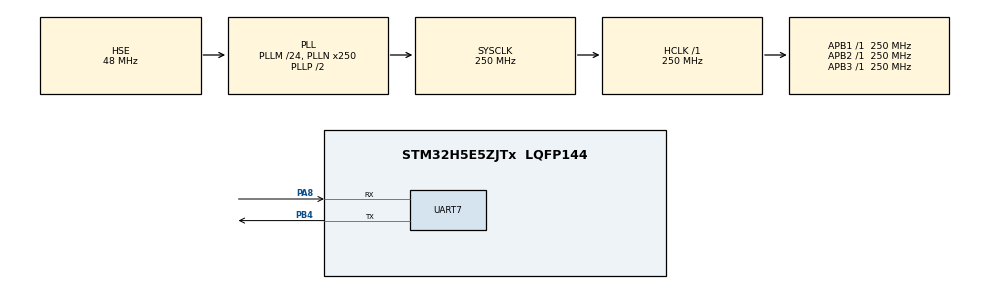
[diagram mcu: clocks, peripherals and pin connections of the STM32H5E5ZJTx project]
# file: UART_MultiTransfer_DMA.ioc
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BOOTPATH.BootPathName=LEGACY
BOOTPATH.UserSelectedBootPath=LEGACY
CORTEX_M33_NS.userName=CORTEX_M33
GPDMA1.TRANSFEREVENTMODE_LL_GPDMACH0=DMA_TCEM_LAST_LL_ITEM_TRANSFER
GPDMA1.TRANSFEREVENTMODE_LL_GPDMACH1=DMA_TCEM_LAST_LL_ITEM_TRANSFER
Linkedlist.MDMA_Channel0.GP_SW.0.BlkHWRequest=DMA_BREQ_SINGLE_BURST
Linkedlist.MDMA_Channel0.GP_SW.0.DataHandling=NONE
Linkedlist.MDMA_Channel0.GP_SW.0.DataSize=0
Linkedlist.MDMA_Channel0.GP_SW.0.DestBurstLength=1
Linkedlist.MDMA_Channel0.GP_SW.0.DestDataWidth=DMA_DEST_DATAWIDTH_BYTE
Linkedlist.MDMA_Channel0.GP_SW.0.DestInc=DMA_DINC_FIXED
Linkedlist.MDMA_Channel0.GP_SW.0.Direction=DMA_MEMORY_TO_PERIPH
Linkedlist.MDMA_Channel0.GP_SW.0.DstAddress=0
Linkedlist.MDMA_Channel0.GP_SW.0.Instance=MDMA_Channel0
Linkedlist.MDMA_Channel0.GP_SW.0.LL_MASTERDMA=GPDMA1
Linkedlist.MDMA_Channel0.GP_SW.0.LL_NAME=UART_Tx_Queue
Linkedlist.MDMA_Channel0.GP_SW.0.LL_TYPE=LINEAR
Linkedlist.MDMA_Channel0.GP_SW.0.Mode=DMA_NORMAL
Linkedlist.MDMA_Channel0.GP_SW.0.NODE_NAME=Node1_tx
Linkedlist.MDMA_Channel0.GP_SW.0.Requestforcodegen=GPDMA1_REQUEST_UART7_TX
Linkedlist.MDMA_Channel0.GP_SW.0.SrcAddress=0
Linkedlist.MDMA_Channel0.GP_SW.0.SrcBurstLength=1
Linkedlist.MDMA_Channel0.GP_SW.0.SrcDataWidth=DMA_SRC_DATAWIDTH_BYTE
Linkedlist.MDMA_Channel0.GP_SW.0.SrcInc=DMA_SINC_INCREMENTED
Linkedlist.MDMA_Channel0.GP_SW.0.TransferAllocatedPortSrc=DMA_SRC_ALLOCATED_PORT0
Linkedlist.MDMA_Channel0.GP_SW.0.TransferEventMode=DMA_TCEM_LAST_LL_ITEM_TRANSFER
Linkedlist.MDMA_Channel0.GP_SW.0.TriggerPolarity=DMA_TRIG_POLARITY_MASKED
Linkedlist.MDMA_Channel0.GP_SW.1.BlkHWRequest=DMA_BREQ_SINGLE_BURST
Linkedlist.MDMA_Channel0.GP_SW.1.DataHandling=NONE
Linkedlist.MDMA_Channel0.GP_SW.1.DataSize=138
Linkedlist.MDMA_Channel0.GP_SW.1.DestBurstLength=1
Linkedlist.MDMA_Channel0.GP_SW.1.DestDataWidth=DMA_DEST_DATAWIDTH_BYTE
Linkedlist.MDMA_Channel0.GP_SW.1.DestInc=DMA_DINC_FIXED
Linkedlist.MDMA_Channel0.GP_SW.1.Direction=DMA_MEMORY_TO_PERIPH
Linkedlist.MDMA_Channel0.GP_SW.1.DstAddress=(uint32_t)&huart7.Instance->TDR
Linkedlist.MDMA_Channel0.GP_SW.1.Instance=MDMA_Channel0
Linkedlist.MDMA_Channel0.GP_SW.1.LL_MASTERDMA=GPDMA1
Linkedlist.MDMA_Channel0.GP_SW.1.LL_NAME=UART_Tx_Queue
Linkedlist.MDMA_Channel0.GP_SW.1.LL_TYPE=LINEAR
Linkedlist.MDMA_Channel0.GP_SW.1.Mode=DMA_NORMAL
Linkedlist.MDMA_Channel0.GP_SW.1.NODE_NAME=Node2_tx
Linkedlist.MDMA_Channel0.GP_SW.1.Requestforcodegen=GPDMA1_REQUEST_UART7_TX
Linkedlist.MDMA_Channel0.GP_SW.1.SrcAddress=(uint32_t)aTxBuffer1
Linkedlist.MDMA_Channel0.GP_SW.1.SrcBurstLength=1
Linkedlist.MDMA_Channel0.GP_SW.1.SrcDataWidth=DMA_SRC_DATAWIDTH_BYTE
Linkedlist.MDMA_Channel0.GP_SW.1.SrcInc=DMA_SINC_INCREMENTED
Linkedlist.MDMA_Channel0.GP_SW.1.TransferAllocatedPortSrc=DMA_SRC_ALLOCATED_PORT0
Linkedlist.MDMA_Channel0.GP_SW.1.TransferEventMode=DMA_TCEM_LAST_LL_ITEM_TRANSFER
Linkedlist.MDMA_Channel0.GP_SW.1.TriggerPolarity=DMA_TRIG_POLARITY_MASKED
Linkedlist.MDMA_Channel0.GP_SW.2.BlkHWRequest=DMA_BREQ_SINGLE_BURST
Linkedlist.MDMA_Channel0.GP_SW.2.DataHandling=NONE
Linkedlist.MDMA_Channel0.GP_SW.2.DataSize=138
Linkedlist.MDMA_Channel0.GP_SW.2.DestBurstLength=1
Linkedlist.MDMA_Channel0.GP_SW.2.DestDataWidth=DMA_DEST_DATAWIDTH_BYTE
Linkedlist.MDMA_Channel0.GP_SW.2.DestInc=DMA_DINC_FIXED
Linkedlist.MDMA_Channel0.GP_SW.2.Direction=DMA_MEMORY_TO_PERIPH
Linkedlist.MDMA_Channel0.GP_SW.2.DstAddress=(uint32_t)&huart7.Instance->TDR
Linkedlist.MDMA_Channel0.GP_SW.2.Instance=MDMA_Channel0
Linkedlist.MDMA_Channel0.GP_SW.2.LL_MASTERDMA=GPDMA1
Linkedlist.MDMA_Channel0.GP_SW.2.LL_NAME=UART_Tx_Queue
Linkedlist.MDMA_Channel0.GP_SW.2.LL_TYPE=LINEAR
Linkedlist.MDMA_Channel0.GP_SW.2.Mode=DMA_NORMAL
Linkedlist.MDMA_Channel0.GP_SW.2.NODE_NAME=Node3_tx
Linkedlist.MDMA_Channel0.GP_SW.2.Requestforcodegen=GPDMA1_REQUEST_UART7_TX
Linkedlist.MDMA_Channel0.GP_SW.2.SrcAddress=(uint32_t)aTxBuffer2
Linkedlist.MDMA_Channel0.GP_SW.2.SrcBurstLength=1
Linkedlist.MDMA_Channel0.GP_SW.2.SrcDataWidth=DMA_SRC_DATAWIDTH_BYTE
Linkedlist.MDMA_Channel0.GP_SW.2.SrcInc=DMA_SINC_INCREMENTED
Linkedlist.MDMA_Channel0.GP_SW.2.TransferAllocatedPortSrc=DMA_SRC_ALLOCATED_PORT0
Linkedlist.MDMA_Channel0.GP_SW.2.TransferEventMode=DMA_TCEM_LAST_LL_ITEM_TRANSFER
Linkedlist.MDMA_Channel0.GP_SW.2.TriggerPolarity=DMA_TRIG_POLARITY_MASKED
Linkedlist.MDMA_Channel0.Request0=GP_SW
Linkedlist.MDMA_Channel0.Request1=GP_SW
Linkedlist.MDMA_Channel0.Request2=GP_SW
Linkedlist.MDMA_Channel0.RequestsNb=3
Linkedlist.MDMA_Channel1.GP_SW.0.BlkHWRequest=DMA_BREQ_SINGLE_BURST
Linkedlist.MDMA_Channel1.GP_SW.0.DataHandling=NONE
Linkedlist.MDMA_Channel1.GP_SW.0.DataSize=0
Linkedlist.MDMA_Channel1.GP_SW.0.DestBurstLength=1
Linkedlist.MDMA_Channel1.GP_SW.0.DestDataWidth=DMA_DEST_DATAWIDTH_BYTE
Linkedlist.MDMA_Channel1.GP_SW.0.DestInc=DMA_DINC_INCREMENTED
Linkedlist.MDMA_Channel1.GP_SW.0.Direction=DMA_PERIPH_TO_MEMORY
Linkedlist.MDMA_Channel1.GP_SW.0.DstAddress=0
Linkedlist.MDMA_Channel1.GP_SW.0.Instance=MDMA_Channel1
Linkedlist.MDMA_Channel1.GP_SW.0.LL_MASTERDMA=GPDMA1
Linkedlist.MDMA_Channel1.GP_SW.0.LL_NAME=UART_Rx_Queue
Linkedlist.MDMA_Channel1.GP_SW.0.LL_TYPE=LINEAR
Linkedlist.MDMA_Channel1.GP_SW.0.Mode=DMA_NORMAL
Linkedlist.MDMA_Channel1.GP_SW.0.NODE_NAME=Node1_rx
Linkedlist.MDMA_Channel1.GP_SW.0.Requestforcodegen=GPDMA1_REQUEST_UART7_RX
Linkedlist.MDMA_Channel1.GP_SW.0.SrcAddress=0
Linkedlist.MDMA_Channel1.GP_SW.0.SrcBurstLength=1
Linkedlist.MDMA_Channel1.GP_SW.0.SrcDataWidth=DMA_SRC_DATAWIDTH_BYTE
Linkedlist.MDMA_Channel1.GP_SW.0.SrcInc=DMA_SINC_FIXED
Linkedlist.MDMA_Channel1.GP_SW.0.TransferAllocatedPortSrc=DMA_SRC_ALLOCATED_PORT0
Linkedlist.MDMA_Channel1.GP_SW.0.TransferEventMode=DMA_TCEM_LAST_LL_ITEM_TRANSFER
Linkedlist.MDMA_Channel1.GP_SW.0.TriggerPolarity=DMA_TRIG_POLARITY_MASKED
Linkedlist.MDMA_Channel1.GP_SW.1.BlkHWRequest=DMA_BREQ_SINGLE_BURST
Linkedlist.MDMA_Channel1.GP_SW.1.DataHandling=NONE
Linkedlist.MDMA_Channel1.GP_SW.1.DataSize=138
Linkedlist.MDMA_Channel1.GP_SW.1.DestBurstLength=1
Linkedlist.MDMA_Channel1.GP_SW.1.DestDataWidth=DMA_DEST_DATAWIDTH_BYTE
Linkedlist.MDMA_Channel1.GP_SW.1.DestInc=DMA_DINC_INCREMENTED
Linkedlist.MDMA_Channel1.GP_SW.1.Direction=DMA_PERIPH_TO_MEMORY
Linkedlist.MDMA_Channel1.GP_SW.1.DstAddress=(uint32_t)aRxBuffer1
Linkedlist.MDMA_Channel1.GP_SW.1.Instance=MDMA_Channel1
Linkedlist.MDMA_Channel1.GP_SW.1.LL_MASTERDMA=GPDMA1
Linkedlist.MDMA_Channel1.GP_SW.1.LL_NAME=UART_Rx_Queue
Linkedlist.MDMA_Channel1.GP_SW.1.LL_TYPE=LINEAR
Linkedlist.MDMA_Channel1.GP_SW.1.Mode=DMA_NORMAL
Linkedlist.MDMA_Channel1.GP_SW.1.NODE_NAME=Node2_rx
Linkedlist.MDMA_Channel1.GP_SW.1.Requestforcodegen=GPDMA1_REQUEST_UART7_RX
Linkedlist.MDMA_Channel1.GP_SW.1.SrcAddress=(uint32_t)&huart7.Instance->RDR
Linkedlist.MDMA_Channel1.GP_SW.1.SrcBurstLength=1
Linkedlist.MDMA_Channel1.GP_SW.1.SrcDataWidth=DMA_SRC_DATAWIDTH_BYTE
Linkedlist.MDMA_Channel1.GP_SW.1.SrcInc=DMA_SINC_FIXED
Linkedlist.MDMA_Channel1.GP_SW.1.TransferAllocatedPortSrc=DMA_SRC_ALLOCATED_PORT0
Linkedlist.MDMA_Channel1.GP_SW.1.TransferEventMode=DMA_TCEM_LAST_LL_ITEM_TRANSFER
Linkedlist.MDMA_Channel1.GP_SW.1.TriggerPolarity=DMA_TRIG_POLARITY_MASKED
Linkedlist.MDMA_Channel1.GP_SW.2.BlkHWRequest=DMA_BREQ_SINGLE_BURST
Linkedlist.MDMA_Channel1.GP_SW.2.DataHandling=NONE
Linkedlist.MDMA_Channel1.GP_SW.2.DataSize=138
Linkedlist.MDMA_Channel1.GP_SW.2.DestBurstLength=1
Linkedlist.MDMA_Channel1.GP_SW.2.DestDataWidth=DMA_DEST_DATAWIDTH_BYTE
Linkedlist.MDMA_Channel1.GP_SW.2.DestInc=DMA_DINC_INCREMENTED
Linkedlist.MDMA_Channel1.GP_SW.2.Direction=DMA_PERIPH_TO_MEMORY
Linkedlist.MDMA_Channel1.GP_SW.2.DstAddress=(uint32_t)aRxBuffer2
Linkedlist.MDMA_Channel1.GP_SW.2.Instance=MDMA_Channel1
Linkedlist.MDMA_Channel1.GP_SW.2.LL_MASTERDMA=GPDMA1
Linkedlist.MDMA_Channel1.GP_SW.2.LL_NAME=UART_Rx_Queue
Linkedlist.MDMA_Channel1.GP_SW.2.LL_TYPE=LINEAR
Linkedlist.MDMA_Channel1.GP_SW.2.Mode=DMA_NORMAL
Linkedlist.MDMA_Channel1.GP_SW.2.NODE_NAME=Node3_rx
Linkedlist.MDMA_Channel1.GP_SW.2.Requestforcodegen=GPDMA1_REQUEST_UART7_RX
Linkedlist.MDMA_Channel1.GP_SW.2.SrcAddress=(uint32_t)&huart7.Instance->RDR
Linkedlist.MDMA_Channel1.GP_SW.2.SrcBurstLength=1
Linkedlist.MDMA_Channel1.GP_SW.2.SrcDataWidth=DMA_SRC_DATAWIDTH_BYTE
Linkedlist.MDMA_Channel1.GP_SW.2.SrcInc=DMA_SINC_FIXED
Linkedlist.MDMA_Channel1.GP_SW.2.TransferAllocatedPortSrc=DMA_SRC_ALLOCATED_PORT0
Linkedlist.MDMA_Channel1.GP_SW.2.TransferEventMode=DMA_TCEM_LAST_LL_ITEM_TRANSFER
Linkedlist.MDMA_Channel1.GP_SW.2.TriggerPolarity=DMA_TRIG_POLARITY_MASKED
Linkedlist.MDMA_Channel1.Request0=GP_SW
Linkedlist.MDMA_Channel1.Request1=GP_SW
Linkedlist.MDMA_Channel1.Request2=GP_SW
Linkedlist.MDMA_Channel1.RequestsNb=3
Linkedlist.RequestSet0=MDMA_Channel0
Linkedlist.RequestSet1=MDMA_Channel1
Linkedlist.RequestSetsNb=2
Mcu.Family=STM32H5
Mcu.Name=STM32H5E5ZJTx
Mcu.Package=LQFP144
NVIC.GPDMA1_Channel0_IRQn=true\:0\:0\:false\:false\:true\:true\:true\:true
NVIC.GPDMA1_Channel1_IRQn=true\:0\:0\:false\:false\:true\:true\:true\:true
NVIC.PriorityGroup=NVIC_PRIORITYGROUP_4
NVIC.UART7_IRQn=true\:0\:0\:false\:false\:true\:true\:true\:true
PA8.GPIO_PuPd=GPIO_PULLUP
PA8.GPIO_Speed=GPIO_SPEED_FREQ_VERY_HIGH
PA8.Mode=Asynchronous
PA8.Signal=UART7_RX
PB4\ (NJTRST).GPIO_PuPd=GPIO_PULLUP
PB4\ (NJTRST).GPIO_Speed=GPIO_SPEED_FREQ_VERY_HIGH
PB4\ (NJTRST).Mode=Asynchronous
PB4\ (NJTRST).Signal=UART7_TX
PH0-OSC_IN(PH0).Mode=HSE-External-Oscillator
PH0-OSC_IN(PH0).Signal=RCC_OSC_IN
PH1-OSC_OUT(PH1).Mode=HSE-External-Oscillator
PH1-OSC_OUT(PH1).Signal=RCC_OSC_OUT
ProjectManager.HeapSize=0x200
ProjectManager.StackSize=0x400
ProjectManager.TargetToolchain=EWARM V9.20
RCC.ADCFreq_Value=250000000
RCC.AHBFreq_Value=250000000
RCC.APB1Freq_Value=250000000
RCC.APB1TimFreq_Value=250000000
RCC.APB2Freq_Value=250000000
RCC.APB2TimFreq_Value=250000000
RCC.APB3Freq_Value=250000000
RCC.CSI_VALUE=4000000
RCC.CortexFreq_Value=250000000
RCC.EPOD_VALUE=48000000
RCC.HCLKFreq_Value=250000000
RCC.HSE_VALUE=48000000
RCC.HSI48_VALUE=48000000
RCC.HSI_VALUE=64000000
RCC.LSE_VALUE=32768
RCC.LSIRC_VALUE=32000
RCC.PLLM=24
RCC.PLLN=250
RCC.PLLSourceVirtual=RCC_PLL1_SOURCE_HSE
RCC.SYSCLKFreq_VALUE=250000000
RCC.SYSCLKSource=RCC_SYSCLKSOURCE_PLLCLK
RCC.USBFreq_Value=258000000
RCC.VCOOutputFreq_Value=500000000
VP_BOOTPATH_VS_BOOTPATH.Mode=BP_Activate
VP_CORTEX_M33_NS_VS_Hclk.Mode=Hclk_Mode
VP_GPDMA1_VS_GPDMACH0.Mode=LINKEDLIST_GPDMACH0
VP_GPDMA1_VS_GPDMACH1.Mode=LINKEDLIST_GPDMACH1
VP_ICACHE_VS_ICACHE.Mode=DefaultMode
VP_PWR_VS_LPOM.Mode=PowerOptimisation
VP_PWR_VS_SECSignals.Mode=Security/Privilege
board=custom

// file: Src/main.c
/* USER CODE BEGIN Header */
/**
  ******************************************************************************
  * @file           : main.c
  * @brief          : Main program body
  ******************************************************************************
  * @attention
  *
  * Copyright (c) 2025 STMicroelectronics.
  * All rights reserved.
  *
  * This software is licensed under terms that can be found in the LICENSE file
  * in the root directory of this software component.
  * If no LICENSE file comes with this software, it is provided AS-IS.
  *
  ******************************************************************************
  */
/* USER CODE END Header */
#include "main.h"

/* USER CODE BEGIN Includes */
#include "linked_list.h"
/* USER CODE END Includes */

/* USER CODE BEGIN PD */
//#define TRANSMITTER_BOARD
/* USER CODE END PD */

DMA_HandleTypeDef handle_GPDMA1_Channel1;
DMA_HandleTypeDef handle_GPDMA1_Channel0;

UART_HandleTypeDef huart7;

/* USER CODE BEGIN PV */
__IO ITStatus UartReady = RESET;
__IO uint32_t UserButtonStatus = 0;  /* set to 1 after User Button interrupt  */
extern DMA_QListTypeDef UART_Tx_Queue;
extern DMA_QListTypeDef UART_Rx_Queue;

/* Buffers used for transmission :
   Size should be a Multiple of cache line size (32 bytes) */
ALIGN_32BYTES (uint8_t aTxBuffer0[]) = "0*****UART_MultiTransfer communication based on DMA Linkedlist*****  *****UART_MultiTransfer communication based on DMA Linkedlist*****0\r\n";
ALIGN_32BYTES (uint8_t aTxBuffer1[]) = "1*****UART_MultiTransfer communication based on DMA Linkedlist*****  *****UART_MultiTransfer communication based on DMA Linkedlist*****1\r\n";
ALIGN_32BYTES (uint8_t aTxBuffer2[]) = "2*****UART_MultiTransfer communication based on DMA Linkedlist*****  *****UART_MultiTransfer communication based on DMA Linkedlist*****2\r\n";
/* Buffer used for reception :
   Size should be a Multiple of cache line size (32 bytes) */
ALIGN_32BYTES (uint8_t aRxBuffer0[RXBUFFERSIZE]);
ALIGN_32BYTES (uint8_t aRxBuffer1[RXBUFFERSIZE]);
ALIGN_32BYTES (uint8_t aRxBuffer2[RXBUFFERSIZE]);
/* USER CODE END PV */

void SystemClock_Config(void);
static void MX_GPIO_Init(void);
static void MX_GPDMA1_Init(void);
static void MX_ICACHE_Init(void);
static void MX_UART7_Init(void);
/* USER CODE BEGIN PFP */
static uint16_t Buffercmp(uint8_t* pBuffer1, uint8_t* pBuffer2, uint16_t BufferLength);
/* USER CODE END PFP */

int main(void)
{

  /* MCU Configuration--------------------------------------------------------*/

  /* Reset of all peripherals, Initializes the Flash interface and the Systick. */
  HAL_Init();

  /* Configure the system clock */
  SystemClock_Config();

  /* USER CODE BEGIN SysInit */
  /* Configure LED1 */
  BSP_LED_Init(LED_GREEN);
  BSP_LED_Init(LED_RED);
  BSP_LED_Init(LED_BLUE);
  /* USER CODE END SysInit */

  /* Initialize all configured peripherals */
  MX_GPIO_Init();
  MX_GPDMA1_Init();
  MX_ICACHE_Init();
  MX_UART7_Init();
  /* USER CODE BEGIN 2 */
  MX_UART_Tx_Queue_Config();
  MX_UART_Rx_Queue_Config();
  /* Link UART queue to DMA channel */
  HAL_DMAEx_List_LinkQ(&handle_GPDMA1_Channel0, &UART_Tx_Queue);

  /* Associate the initialized GPDMA handle to the UART handle */
  __HAL_LINKDMA(&huart7, hdmatx, handle_GPDMA1_Channel0);
  /* Link UART queue to DMA channel */
  HAL_DMAEx_List_LinkQ(&handle_GPDMA1_Channel1, &UART_Rx_Queue);

  /* Associate the initialized GPDMA handle to the UART handle */
  __HAL_LINKDMA(&huart7, hdmarx, handle_GPDMA1_Channel1);

#ifdef TRANSMITTER_BOARD

  /* Configure User push-button in Interrupt mode */
  BSP_PB_Init(BUTTON_USER, BUTTON_MODE_EXTI);

  /* Wait for User push-button press before starting the Communication.
     In the meantime, LED2 is blinking */
  while(UserButtonStatus == 0)
  {
      /* Toggle LED3*/
      BSP_LED_Toggle(LED_BLUE);
      HAL_Delay(100);
  }

  BSP_LED_Off(LED_BLUE);

  /* The board sends the message and expects to receive it back */

  /*##-2- Start the transmission process #####################################*/
  /* While the UART in reception process, user can transmit data through
     "aTxBuffer" buffer */
  if(HAL_UART_Transmit_DMA(&huart7, (uint8_t*)aTxBuffer0, TXBUFFERSIZE)!= HAL_OK)
  {
    Error_Handler();
  }

  /*##-3- Wait for the end of the transfer ###################################*/
  while (UartReady != SET)
  {
  }

  /* Reset transmission flag */
  UartReady = RESET;

  /*##-4- Put UART peripheral in reception process ###########################*/
  if(HAL_UART_Receive_DMA(&huart7, (uint8_t *)aRxBuffer0, RXBUFFERSIZE) != HAL_OK)
  {
    Error_Handler();
  }

#else

  /* The board receives the message and sends it back */

  /*##-2- Put UART peripheral in reception process ###########################*/
  if(HAL_UART_Receive_DMA(&huart7, (uint8_t *)aRxBuffer0, RXBUFFERSIZE) != HAL_OK)
  {
    Error_Handler();
  }

  /*##-3- Wait for the end of the transfer ###################################*/
  /* While waiting for message to come from the other board, LED2 is
     blinking according to the following pattern: a double flash every half-second */
  while (UartReady != SET)
  {
      BSP_LED_On(LED_BLUE);
      HAL_Delay(100);
      BSP_LED_Off(LED_BLUE);
      HAL_Delay(100);
      BSP_LED_On(LED_BLUE);
      HAL_Delay(100);
      BSP_LED_Off(LED_BLUE);
      HAL_Delay(500);
  }

  /* Reset transmission flag */
  UartReady = RESET;
  BSP_LED_Off(LED_BLUE);

  /*##-4- Start the transmission process #####################################*/
  if(HAL_UART_Transmit_DMA(&huart7, (uint8_t*)aTxBuffer0, TXBUFFERSIZE)!= HAL_OK)
  {
    Error_Handler();
  }

#endif /* TRANSMITTER_BOARD */

  /*##-5- Wait for the end of the transfer ###################################*/
  while (UartReady != SET)
  {
  }

  /* Reset transmission flag */
  UartReady = RESET;

  /*##-6- Compare the sent and received buffers ##############################*/
  if((Buffercmp((uint8_t*)aTxBuffer0,(uint8_t*)aRxBuffer0,RXBUFFERSIZE) != 0) ||\
     (Buffercmp((uint8_t*)aTxBuffer1,(uint8_t*)aRxBuffer1,RXBUFFERSIZE) != 0) ||\
     (Buffercmp((uint8_t*)aTxBuffer2,(uint8_t*)aRxBuffer2,RXBUFFERSIZE) != 0))
  {
    Error_Handler();
  }

  /* Turn on LED1 if test passes then enter infinite loop */
  BSP_LED_On(LED_GREEN);
  /* USER CODE END 2 */

  /* Infinite loop */
  while (1)
  {

  }
}

void SystemClock_Config(void)
{
  RCC_OscInitTypeDef RCC_OscInitStruct = {0};
  RCC_ClkInitTypeDef RCC_ClkInitStruct = {0};

  /** Configure the main internal regulator output voltage
  */
  __HAL_PWR_VOLTAGESCALING_CONFIG(PWR_REGULATOR_VOLTAGE_SCALE0);

  while(!__HAL_PWR_GET_FLAG(PWR_FLAG_VOSRDY)) {}

  /** Initializes the RCC Oscillators according to the specified parameters
  * in the RCC_OscInitTypeDef structure.
  */
  RCC_OscInitStruct.OscillatorType = RCC_OSCILLATORTYPE_HSE;
  RCC_OscInitStruct.HSEState = RCC_HSE_ON;
  RCC_OscInitStruct.PLL.PLLState = RCC_PLL_ON;
  RCC_OscInitStruct.PLL.PLLSource = RCC_PLL1_SOURCE_HSE;
  RCC_OscInitStruct.PLL.PLLM = 24;
  RCC_OscInitStruct.PLL.PLLN = 250;
  RCC_OscInitStruct.PLL.PLLP = 2;
  RCC_OscInitStruct.PLL.PLLQ = 2;
  RCC_OscInitStruct.PLL.PLLR = 2;
  RCC_OscInitStruct.PLL.PLLRGE = RCC_PLL1_VCIRANGE_1;
  RCC_OscInitStruct.PLL.PLLVCOSEL = RCC_PLL1_VCORANGE_WIDE;
  RCC_OscInitStruct.PLL.PLLFRACN = 0;
  if (HAL_RCC_OscConfig(&RCC_OscInitStruct) != HAL_OK)
  {
    Error_Handler();
  }

  /** Initializes the CPU, AHB and APB buses clocks
  */
  RCC_ClkInitStruct.ClockType = RCC_CLOCKTYPE_HCLK|RCC_CLOCKTYPE_SYSCLK
                              |RCC_CLOCKTYPE_PCLK1|RCC_CLOCKTYPE_PCLK2
                              |RCC_CLOCKTYPE_PCLK3;
  RCC_ClkInitStruct.SYSCLKSource = RCC_SYSCLKSOURCE_PLLCLK;
  RCC_ClkInitStruct.AHBCLKDivider = RCC_SYSCLK_DIV1;
  RCC_ClkInitStruct.APB1CLKDivider = RCC_HCLK_DIV1;
  RCC_ClkInitStruct.APB2CLKDivider = RCC_HCLK_DIV1;
  RCC_ClkInitStruct.APB3CLKDivider = RCC_HCLK_DIV1;

  if (HAL_RCC_ClockConfig(&RCC_ClkInitStruct, FLASH_LATENCY_5) != HAL_OK)
  {
    Error_Handler();
  }

  /** Configure the programming delay
  */
  __HAL_FLASH_SET_PROGRAM_DELAY(FLASH_PROGRAMMING_DELAY_2);
}

static void MX_GPDMA1_Init(void)
{

  /* Peripheral clock enable */
  __HAL_RCC_GPDMA1_CLK_ENABLE();

  /* GPDMA1 interrupt Init */
    HAL_NVIC_SetPriority(GPDMA1_Channel0_IRQn, 0, 0);
    HAL_NVIC_EnableIRQ(GPDMA1_Channel0_IRQn);
    HAL_NVIC_SetPriority(GPDMA1_Channel1_IRQn, 0, 0);
    HAL_NVIC_EnableIRQ(GPDMA1_Channel1_IRQn);

  handle_GPDMA1_Channel1.Instance = GPDMA1_Channel1;
  handle_GPDMA1_Channel1.InitLinkedList.Priority = DMA_LOW_PRIORITY_LOW_WEIGHT;
  handle_GPDMA1_Channel1.InitLinkedList.LinkStepMode = DMA_LSM_FULL_EXECUTION;
  handle_GPDMA1_Channel1.InitLinkedList.LinkAllocatedPort = DMA_LINK_ALLOCATED_PORT0;
  handle_GPDMA1_Channel1.InitLinkedList.TransferEventMode = DMA_TCEM_LAST_LL_ITEM_TRANSFER;
  handle_GPDMA1_Channel1.InitLinkedList.LinkedListMode = DMA_LINKEDLIST_NORMAL;
  if (HAL_DMAEx_List_Init(&handle_GPDMA1_Channel1) != HAL_OK)
  {
    Error_Handler();
  }
  if (HAL_DMA_ConfigChannelAttributes(&handle_GPDMA1_Channel1, DMA_CHANNEL_NPRIV) != HAL_OK)
  {
    Error_Handler();
  }
  handle_GPDMA1_Channel0.Instance = GPDMA1_Channel0;
  handle_GPDMA1_Channel0.InitLinkedList.Priority = DMA_LOW_PRIORITY_LOW_WEIGHT;
  handle_GPDMA1_Channel0.InitLinkedList.LinkStepMode = DMA_LSM_FULL_EXECUTION;
  handle_GPDMA1_Channel0.InitLinkedList.LinkAllocatedPort = DMA_LINK_ALLOCATED_PORT0;
  handle_GPDMA1_Channel0.InitLinkedList.TransferEventMode = DMA_TCEM_LAST_LL_ITEM_TRANSFER;
  handle_GPDMA1_Channel0.InitLinkedList.LinkedListMode = DMA_LINKEDLIST_NORMAL;
  if (HAL_DMAEx_List_Init(&handle_GPDMA1_Channel0) != HAL_OK)
  {
    Error_Handler();
  }
  if (HAL_DMA_ConfigChannelAttributes(&handle_GPDMA1_Channel0, DMA_CHANNEL_NPRIV) != HAL_OK)
  {
    Error_Handler();
  }

}

static void MX_ICACHE_Init(void)
{

  /** Enable instruction cache (default 2-ways set associative cache)
  */
  if (HAL_ICACHE_Enable() != HAL_OK)
  {
    Error_Handler();
  }

}

static void MX_UART7_Init(void)
{

  huart7.Instance = UART7;
  huart7.Init.BaudRate = 115200;
  huart7.Init.WordLength = UART_WORDLENGTH_8B;
  huart7.Init.StopBits = UART_STOPBITS_1;
  huart7.Init.Parity = UART_PARITY_NONE;
  huart7.Init.Mode = UART_MODE_TX_RX;
  huart7.Init.HwFlowCtl = UART_HWCONTROL_NONE;
  huart7.Init.OverSampling = UART_OVERSAMPLING_16;
  huart7.Init.OneBitSampling = UART_ONE_BIT_SAMPLE_DISABLE;
  huart7.Init.ClockPrescaler = UART_PRESCALER_DIV1;
  huart7.AdvancedInit.AdvFeatureInit = UART_ADVFEATURE_NO_INIT;
  if (HAL_UART_Init(&huart7) != HAL_OK)
  {
    Error_Handler();
  }
  if (HAL_UARTEx_SetTxFifoThreshold(&huart7, UART_TXFIFO_THRESHOLD_1_8) != HAL_OK)
  {
    Error_Handler();
  }
  if (HAL_UARTEx_SetRxFifoThreshold(&huart7, UART_RXFIFO_THRESHOLD_1_8) != HAL_OK)
  {
    Error_Handler();
  }
  if (HAL_UARTEx_DisableFifoMode(&huart7) != HAL_OK)
  {
    Error_Handler();
  }

}

static void MX_GPIO_Init(void)
{

  /* GPIO Ports Clock Enable */
  __HAL_RCC_GPIOH_CLK_ENABLE();

}

/* USER CODE BEGIN 4 */

/**
  * @brief  Tx Transfer completed callback
  * @param  UartHandle: UART handle.
  * @note   This example shows a simple way to report end of DMA Tx transfer, and
  *         you can add your own implementation.
  * @retval None
  */
void HAL_UART_TxCpltCallback(UART_HandleTypeDef *UartHandle)
{
  /* Set transmission flag: transfer complete */
  UartReady = SET;
}

/**
  * @brief  Rx Transfer completed callback
  * @param  UartHandle: UART handle
  * @note   This example shows a simple way to report end of DMA Rx transfer, and
  *         you can add your own implementation.
  * @retval None
  */
void HAL_UART_RxCpltCallback(UART_HandleTypeDef *UartHandle)
{
  /* Set transmission flag: transfer complete */
  UartReady = SET;
}

/**
  * @brief  UART error callbacks
  * @param  UartHandle: UART handle
  * @note   This example shows a simple way to report transfer error, and you can
  *         add your own implementation.
  * @retval None
  */
void HAL_UART_ErrorCallback(UART_HandleTypeDef *UartHandle)
{
    Error_Handler();
}

/**
  * @brief EXTI line detection callbacks
  * @param GPIO_Pin: Specifies the pins connected EXTI line
  * @retval None
  */
void BSP_PB_Callback(Button_TypeDef Button)
{
  if(Button == BUTTON_USER)
  {
    UserButtonStatus = 1;
  }
}

/**
  * @brief  Compares two buffers.
  * @param  pBuffer1, pBuffer2: buffers to be compared.
  * @param  BufferLength: buffer's length
  * @retval 0  : pBuffer1 identical to pBuffer2
  *         >0 : pBuffer1 differs from pBuffer2
  */
static uint16_t Buffercmp(uint8_t* pBuffer1, uint8_t* pBuffer2, uint16_t BufferLength)
{
  while (BufferLength--)
  {
    if ((*pBuffer1) != *pBuffer2)
    {
      return BufferLength;
    }
    pBuffer1++;
    pBuffer2++;
  }

  return 0;
}
/* USER CODE END 4 */

void Error_Handler(void)
{
  /* USER CODE BEGIN Error_Handler_Debug */
  /* User can add his own implementation to report the HAL error return state */
  __disable_irq();
  while (1)
  {
    BSP_LED_On(LED_RED);
  }
  /* USER CODE END Error_Handler_Debug */
}
